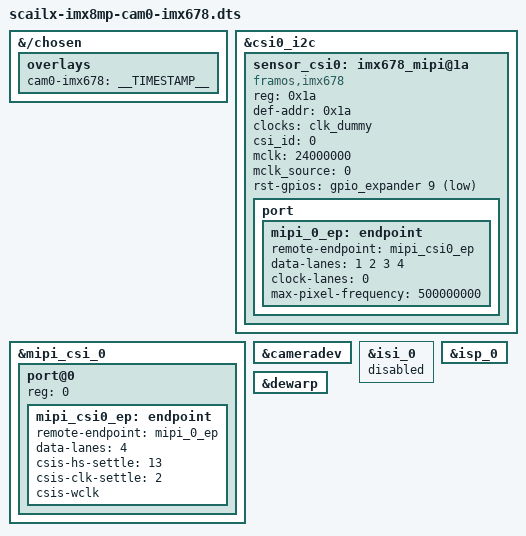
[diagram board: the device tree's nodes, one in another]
// SPDX-License-Identifier: (GPL-2.0 OR MIT)
/*
 * Copyright (C) 2023 VideologyInc
 *
 */

/dts-v1/;
/plugin/;

#include <dt-bindings/clock/imx8mp-clock.h>
#include <dt-bindings/gpio/gpio.h>

&{/chosen} {
	overlays {
		cam0-imx678 = __TIMESTAMP__;
	};
};

&csi0_i2c {
	#address-cells = <1>;
	#size-cells = <0>;

	sensor_csi0: imx678_mipi@1a {
		compatible = "framos,imx678";
		reg = <0x1a>;
		def-addr = <0x1a>;
		clocks = <&clk_dummy>;
		clock-names = "csi_mclk";
		csi_id = <0>;
		mclk = <24000000>;
		mclk_source = <0>;
		status = "okay";
		rst-gpios = <&gpio_expander 9 GPIO_ACTIVE_LOW>;

		port {
			mipi_0_ep: endpoint {
				remote-endpoint = <&mipi_csi0_ep>;
				data-lanes = <1 2 3 4>;
				clock-lanes = <0>;
				max-pixel-frequency = /bits/ 64 <500000000>;
			};
		};
	};
};

&mipi_csi_0 {
	status = "okay";
	#address-cells = <1>;
	#size-cells = <0>;

	port@0 {
		reg = <0>;
		mipi_csi0_ep: endpoint {
			remote-endpoint = <&mipi_0_ep>;
			data-lanes = <4>;
			csis-hs-settle = <13>;
			csis-clk-settle = <2>;
			csis-wclk;
		};
	};
};

&cameradev {
	status = "okay";
};

&isi_0 {
	status = "disabled";
};

&isp_0 {
	status = "okay";
};

&dewarp {
	status = "okay";
};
